# A31S13x register map
Vendor: VENDOR ABOV Semiconductor Co., Ltd.; Series: A31S13x; File version: 1.0
CPU: CM0+ r0p1, little endian, no MPU, no FPU, VTOR, 2 interrupt priority bits
Registers are 32-bit, read-write, reset 0x0 unless marked. A register's access mark holds for its fields unless they carry their own. Offsets are from the block's base; [hi:lo] are bit positions.

## FMC — Flash Memory Controller
Base 0x40001B00
0x00 ADR reset 0x5FFFFF80 — Flash Memory Address Register
  [31:0] ADDR — Flash Memory Address Pointer
0x04 IDR1 — Flash Memory Identification Register 1
  [31:0] ID1 — Flash Memory Identification 1
    0x8192A3B=Value (ID1 Value (0x08192a3b))
0x08 IDR2 — Flash Memory Identification Register 2
  [31:0] ID2 — Flash Memory Identification 2
    0x4C5D6E7F=Value (ID2 Value (0x4c5d6e7f))
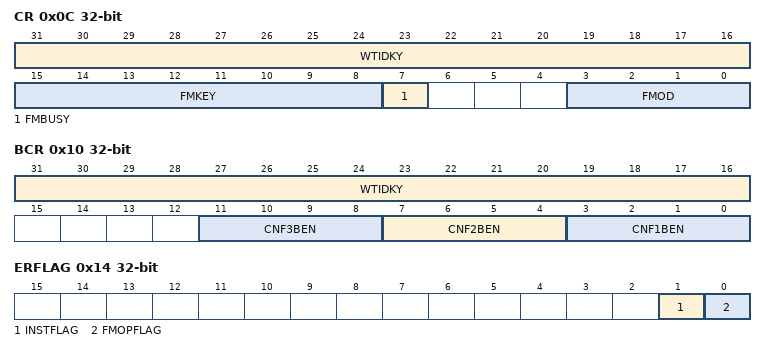
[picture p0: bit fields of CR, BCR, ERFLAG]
0x0C CR — Flash Memory Control Register
  [31:16] WTIDKY wo — Write Identification Key (0x6c93)
    0x6C93=Value (Key Value (0x6c93))
  [15:8] FMKEY — Flash Memory Operation Area Selection
    0=NoSelect (Not select any area but for flash page buffer reset mode); 56=ConfigurationOptionArea (Select 'configure option area' for flash memory erase/write); 164=Flash (Select 'flash memory area' for flash memory erase/write)
  [7] FMBUSY ro — Flash Memory Operation Mode Busy
    0=NoEffect; 1=Busy
  [3:0] FMOD — Flash Memory Operation Mode Selection
    1=PageBufferReset ('Flash page buffer reset mode' and start regardless of the flash operation rule); 2=PageErase ('Flash page erase mode' and start when the flash operation rule is satisfied.); 4=PageWrite ('Flash page write mode' and start when the flash operation rule is satisfied.); 8=BulkErase ('Flash bulk erase mode' and start when the flash operation rule is satisfied.)
0x10 BCR — Flash Memory Configure Area Bulk Erase Control Register
  [31:16] WTIDKY wo — Write Identification Key (0xc1be)
    0xC1BE=Value (Key Value (0xc1be))
  [11:8] CNF3BEN — Configure Option Page 3 Bulk Erase Enable
    5=Enable (Permit 'configure option page 3' erase when bulk erase)
  [7:4] CNF2BEN — Configure Option Page 2 Bulk Erase Enable
    5=Enable (Permit 'configure option page 2' erase when bulk erase)
  [3:0] CNF1BEN — Configure Option Page 1 Bulk Erase Enable
    5=Enable (Permit 'configure option page 1' erase when bulk erase)
0x14 ERFLAG — Flash Memory Error Flag
  [1] INSTFLAG — Don't care
  [0] FMOPFLAG — Error bit of Flash Memory Operation Procedure
    0=NoWrongProcedure; 1=WrongProcedure (A wrong procedure occurred, This bit is cleared to '0' when write '1'.)
0x100 PAGEBUF wo — Flash Memory Page Buffer Area (256bytes/Accessed by 32bit Word Only)

## DFMC — Data Flash Memory Controller
Base 0x40001D00
0x00 DADR reset 0x5FFF9990 — Data Flash Memory Address Register
  [31:0] ADDR — Data Flash Memory Address Pointer
0x04 DIDR1 — Data Flash Memory Identification Register 1
  [31:0] ID1 — Data Flash Memory Identification 1
    0xA9C46E91=Value (ID1 Value (0xa9c46e91))
0x08 DIDR2 — Data Flash Memory Identification Register 2
  [31:0] ID2 — Data Flash Memory Identification 2
    0x78F5B3D2=Value (ID2 Value (0x78f5b3d2))
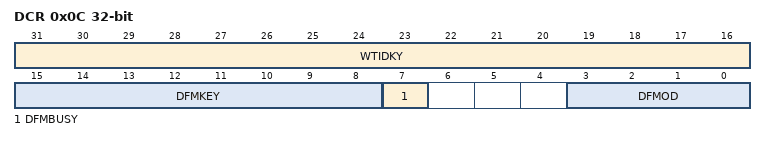
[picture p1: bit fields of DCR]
0x0C DCR — Data Flash Memory Control Register
  [31:16] WTIDKY wo — Write Identification Key (0xb69c)
    0xB69C=Value (Key Value (0xb69c))
  [15:8] DFMKEY — Data Flash Memory Operation Area Selection
    0=NoSelect (Not select any area but for data flash page buffer reset mode); 164=DataFlash (Select 'data flash memory area' for data flash memory erase/write)
  [7] DFMBUSY ro — Data Flash Memory Operation Mode Busy
    0=NoEffect; 1=Busy
  [3:0] DFMOD — Data Flash Memory Operation Mode Selection
    1=PageBufferReset ('Data flash page buffer reset mode' and start regardless of the operation rule); 2=PageErase ('Data flash page erase mode' and start when the operation rule is satisfied.); 4=PageWrite ('Data flash page write mode' and start when the operation rule is satisfied.); 8=BulkErase ('Data flash bulk erase mode' and start when the operation rule is satisfied.)
0x14 DERFLAG — Data Flash Memory Error Flag
  [0] DFMOPFLAG — Error bit of Data Flash Memory Operation Procedure
    0=NoWrongProcedure; 1=WrongProcedure (A wrong procedure occurred, This bit is cleared to '0' when write '1'.)
0x100 DPAGEBUF wo — Data Flash Memory Page Buffer Area (32bytes/Accessed by 32bit Word Only)
